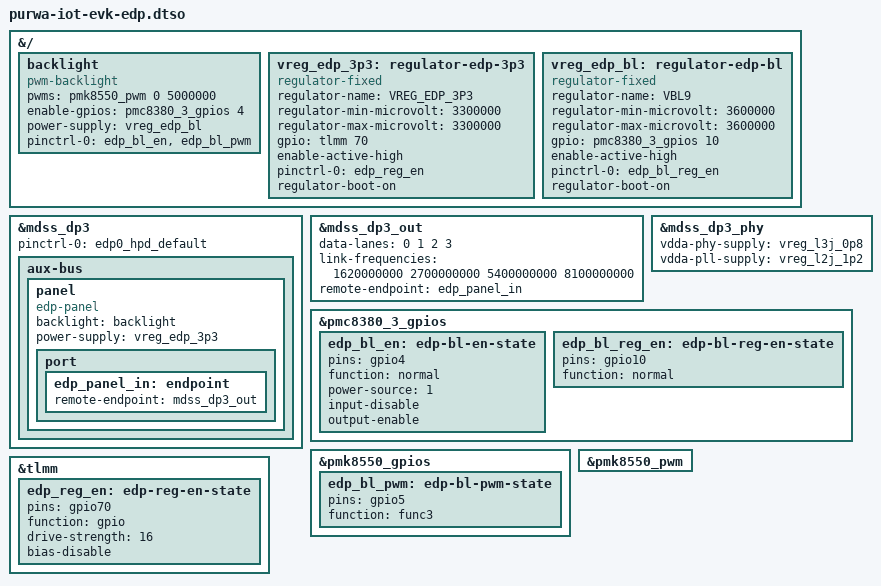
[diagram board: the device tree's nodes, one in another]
// SPDX-License-Identifier: BSD-3-Clause
/*
 * Copyright (c) Qualcomm Technologies, Inc. and/or its subsidiaries.
 */

/dts-v1/;
/plugin/;

#include <dt-bindings/gpio/gpio.h>

&{/} {
	backlight: backlight {
		compatible = "pwm-backlight";
		pwms = <&pmk8550_pwm 0 5000000>;
		enable-gpios = <&pmc8380_3_gpios 4 GPIO_ACTIVE_HIGH>;
		power-supply = <&vreg_edp_bl>;

		pinctrl-0 = <&edp_bl_en>, <&edp_bl_pwm>;
		pinctrl-names = "default";
	};

	vreg_edp_3p3: regulator-edp-3p3 {
		compatible = "regulator-fixed";

		regulator-name = "VREG_EDP_3P3";
		regulator-min-microvolt = <3300000>;
		regulator-max-microvolt = <3300000>;

		gpio = <&tlmm 70 GPIO_ACTIVE_HIGH>;
		enable-active-high;

		pinctrl-0 = <&edp_reg_en>;
		pinctrl-names = "default";

		regulator-boot-on;
	};

	vreg_edp_bl: regulator-edp-bl {
		compatible = "regulator-fixed";

		regulator-name = "VBL9";
		regulator-min-microvolt = <3600000>;
		regulator-max-microvolt = <3600000>;

		gpio = <&pmc8380_3_gpios 10 GPIO_ACTIVE_HIGH>;
		enable-active-high;

		pinctrl-0 = <&edp_bl_reg_en>;
		pinctrl-names = "default";

		regulator-boot-on;
	};
};

&mdss_dp3 {
	pinctrl-0 = <&edp0_hpd_default>;
	pinctrl-names = "default";

	status = "okay";

	aux-bus {
		panel {
			compatible = "edp-panel";

			backlight = <&backlight>;
			power-supply = <&vreg_edp_3p3>;

			port {
				edp_panel_in: endpoint {
					remote-endpoint = <&mdss_dp3_out>;
				};
			};
		};
	};
};

&mdss_dp3_out {
	data-lanes = <0 1 2 3>;
	link-frequencies = /bits/ 64 <1620000000 2700000000 5400000000 8100000000>;

	remote-endpoint = <&edp_panel_in>;
};

&mdss_dp3_phy {
	vdda-phy-supply = <&vreg_l3j_0p8>;
	vdda-pll-supply = <&vreg_l2j_1p2>;

	status = "okay";
};

&pmc8380_3_gpios {
	edp_bl_en: edp-bl-en-state {
		pins = "gpio4";
		function = "normal";
		power-source = <1>;
		input-disable;
		output-enable;
	};

	edp_bl_reg_en: edp-bl-reg-en-state {
		pins = "gpio10";
		function = "normal";
	};
};

&pmk8550_gpios {
	edp_bl_pwm: edp-bl-pwm-state {
		pins = "gpio5";
		function = "func3";
	};
};

&pmk8550_pwm {
	status = "okay";
};

&tlmm {
	edp_reg_en: edp-reg-en-state {
		pins = "gpio70";
		function = "gpio";
		drive-strength = <16>;
		bias-disable;
	};
};
